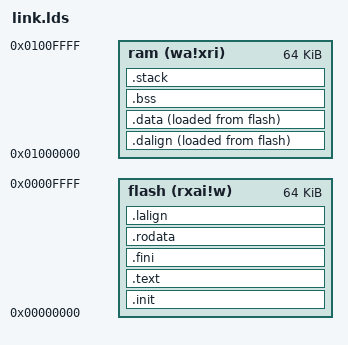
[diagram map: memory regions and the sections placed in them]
OUTPUT_ARCH( "riscv" )

ENTRY( _start )

MEMORY
{
  flash (rxai!w) : ORIGIN = 0x00000000, LENGTH = 64K
  ram   (wa!xri) : ORIGIN = 0x01000000, LENGTH = 64K
}

SECTIONS
{
  __stack_size = DEFINED(__stack_size) ? __stack_size : 1K;

  .init           :
  {
    KEEP (*(SORT_NONE(.init)))
  } >flash AT>flash

  .text           :
  {
    *(.text.unlikely .text.unlikely.*)
    *(.text.startup .text.startup.*)
    *(.text .text.*)
    *(.gnu.linkonce.t.*)
  } >flash AT>flash

  .fini           :
  {
    KEEP (*(SORT_NONE(.fini)))
  } >flash AT>flash :flash

  PROVIDE (__etext = .);
  PROVIDE (_etext = .);
  PROVIDE (etext = .);

  . = ALIGN(4);

  .rodata         :
  {
    *(.rdata)
    *(.rodata .rodata.*)
    *(.gnu.linkonce.r.*)
  } >flash AT>flash

  . = ALIGN(4);

  .lalign         :
  {
    . = ALIGN(4);
    PROVIDE( _data_lma = . );
  } >flash AT>flash

  .dalign         :
  {
    . = ALIGN(4);
    PROVIDE( _data = . );
  } >ram AT>flash

  .data          :
  {
    *(.data .data.*)
    *(.gnu.linkonce.d.*)
    . = ALIGN(4);
    PROVIDE( __global_pointer$ = . + 0x800 );
    *(.sdata .sdata.*)
    *(.gnu.linkonce.s.*)
    . = ALIGN(4);
    *(.srodata.cst16)
    *(.srodata.cst8)
    *(.srodata.cst4)
    *(.srodata.cst2)
    *(.srodata .srodata.*)
  } >ram AT>flash

  . = ALIGN(4);

  PROVIDE( _edata = . );
  PROVIDE( edata = . );

  PROVIDE( _fbss = . );
  PROVIDE( __bss_start = . );

  .bss            :
  {
    *(.sbss*)
    *(.gnu.linkonce.sb.*)
    *(.bss .bss.*)
    *(.gnu.linkonce.b.*)
    *(COMMON)
    . = ALIGN(4);
  } >ram AT>ram

  . = ALIGN(4);

  PROVIDE( _end = . );
  PROVIDE( end = . );

  .stack ORIGIN(ram) + LENGTH(ram) - __stack_size :
  {
    PROVIDE( _heap_end = . );
    . = __stack_size;
    PROVIDE( _sp = . );
  } >ram AT>ram
}
